# DCB register map
Vendor: Texas Instruments
Peripheral module from a debugger description file (folder CC23x0R2).
Registers are 32-bit, access per field, reset 0x0 unless marked. A register's access mark holds for its fields unless they carry their own. Offsets are as the file gives them; lines under a group give offsets from that group; [hi:lo] are bit positions; {n}, {i} and the like mark numbered series; 'fields as' and 'values as' point back to an identical list; <NAME> marks a mode.

## DCB
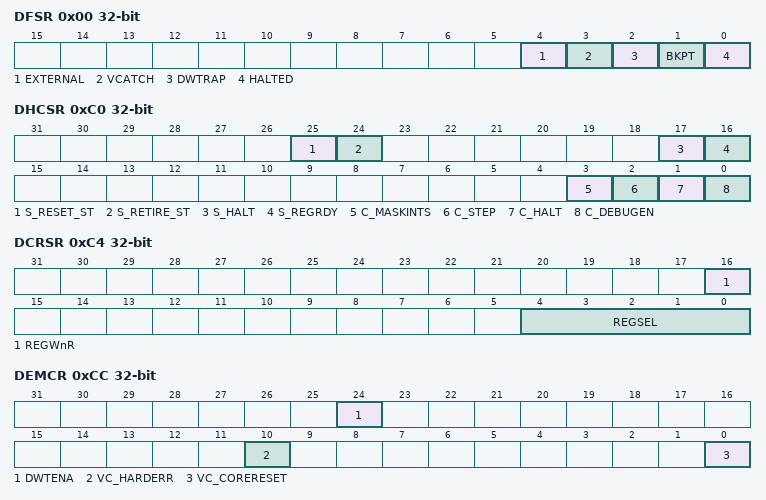
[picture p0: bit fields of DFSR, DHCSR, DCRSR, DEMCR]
0x00 DFSR — Debug Fault Status Register Use the Debug Fault Status Register to monitor external debug requests, vector catches, data watchpoint match, BKPT instruction execution and BPU comparator matches, halt requests. Write one to clear. C_DEBUGEN must be set before any bits in DFSR are updated.
  [4] EXTERNAL rw — External debug request flag 0x0:No edbgrq external debug request occurred 0x1:Edbgrq has halted the core
  [3] VCATCH rw — Vector catch flag. When the VCATCH flag is set, a flag in the Debug Exception and Monitor Control Register is also set to indicate the type of vector catch. 0x0:No vector catch occurred 0x1:Vector catch occurred
  [2] DWTRAP rw — Data Watchpoint (DW) flag. 0x0:No dw match 0x1:Dw match
  [1] BKPT rw — The BKPT flag is set by the execution of the BKPT instruction or on an instruction whose address triggered the breakpoint comparator match. When the processor has halted, the return PC points to the address of the breakpointed instruction. 0x0:No bkpt instruction or hardware breakpoint match 0x1:Bkpt instruction or hardware breakpoint match
  [0] HALTED rw — Halt request flag 0x0:No halt request 0x1:Halt requested by dap access to c_halt or halted with c_step asserted
0xC0 DHCSR — Debug Halting Control and Status Register The purpose of the Debug Halting Control and Status Register (DHCSR) is to provide status information about the state of the processor, enable core debug, halt and step the processor. For writes, 0xA05F must be written to bits [31:16], otherwise the write operation is ignored and no bits are written into the register.
  [25] S_RESET_ST ro — Indicates that the core has been reset, or is now being reset, since the last time this bit was read. This a sticky bit that clears on read. So, reading twice and getting 1 then 0 means it was reset in the past. Reading twice and getting 1 both times means that it is currently reset and held in reset.
  [24] S_RETIRE_ST ro — Core has retired at least part of an instruction since last read. This is a sticky bit that clears on read.
  [17] S_HALT ro — The core is halted in debug state only if S_HALT is set.
  [16] S_REGRDY ro — Register Read/Write to the Debug Core Register Selector Register is available. Set in response to a successful register access.
  [3] C_MASKINTS rw — When this bit is set and debug is enabled, external interrupts, SysTick, and PendSV are masked. Does not affect NMI, Hard Fault or SVCall. When C_DEBUGEN = 0, this bit has no effect.
  [2] C_STEP rw — Causes a debug event on any instruction or exception being executed, resulting in the core single stepping.
  [1] C_HALT rw — Halts the core. This bit is set automatically when the core triggers a debug event, for example, on a breakpoint. This bit clears on core reset. When C_DEBUGEN = 0, this bit has no effect.
  [0] C_DEBUGEN rw — Enables or disable debug
    1=DBG_EN (Debug enabled); 0=DBG_DIS (Debug disabled)
0xC4 DCRSR — Debug Core Register Selector Register The purpose of the Debug Core Register Selector Register (DCRSR) is to select the processor register to transfer data to or from.
  [16] REGWnR wo — Register Write-not-Read 0x0:Read 0x1:Write
  [4:0] REGSEL wo — Select processor register 0x00:R0 0x01:R1 0x02:R2 0x03:R3 0x04:R4 0x05:R5 0x06:R6 0x07:R7 0x08:R8 0x09:R9 0x0a:R10 0x0b:R11 0x0c:R12 0x0d:Current sp 0x0e:Lr 0x0f:Debug Return Address 0x10:Xpsr flags, execution number, and state information 0x11:Msp (main sp) 0x12:Psp (process sp) 0x14:Control (dcrdr[25:24]), primask (dcrdr[0])
0xC8 DCRDR rw — Debug Core Register Data Register The purpose of the Debug Core Register Data Register (DCRDR) is to hold data read from or written to core registers.
  [31:0] DBGTMP — Data temporary cache, for reading and writing registers.
0xCC DEMCR — Debug Exception and Monitor Control Register The purpose of the Debug Exception and Monitor Control Register (DEMCR) is: Global enable for the DW unit, Vector catching (that is, causes debug entry on execution of a specified vector.)
  [24] DWTENA rw — Global enable or disable for the DW unit 0x0:Dw unit disabled. watchpoint cannot halt the core. the dw pcsr reads as oxffffffff. 0x1:Dw unit enabled
  [10] VC_HARDERR rw — Debug trap on a Hard Fault
  [0] VC_CORERESET rw — Reset Vector Catch. Halt running system if HRESETn is asserted
